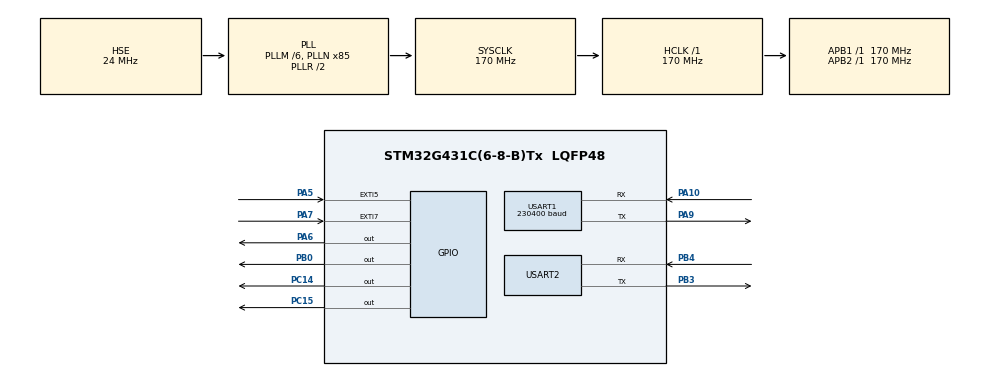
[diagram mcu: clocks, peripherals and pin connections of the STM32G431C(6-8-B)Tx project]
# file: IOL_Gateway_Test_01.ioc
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Dma.Request0=USART1_RX
Dma.Request1=USART2_RX
Dma.USART1_RX.0.Direction=DMA_PERIPH_TO_MEMORY
Dma.USART1_RX.0.EventEnable=DISABLE
Dma.USART1_RX.0.Instance=DMA1_Channel1
Dma.USART1_RX.0.MemDataAlignment=DMA_MDATAALIGN_BYTE
Dma.USART1_RX.0.MemInc=DMA_MINC_ENABLE
Dma.USART1_RX.0.Mode=DMA_NORMAL
Dma.USART1_RX.0.PeriphDataAlignment=DMA_PDATAALIGN_BYTE
Dma.USART1_RX.0.PeriphInc=DMA_PINC_DISABLE
Dma.USART1_RX.0.Polarity=HAL_DMAMUX_REQ_GEN_RISING
Dma.USART1_RX.0.Priority=DMA_PRIORITY_LOW
Dma.USART1_RX.0.RequestNumber=1
Dma.USART1_RX.0.SignalID=NONE
Dma.USART1_RX.0.SyncEnable=DISABLE
Dma.USART1_RX.0.SyncPolarity=HAL_DMAMUX_SYNC_NO_EVENT
Dma.USART1_RX.0.SyncRequestNumber=1
Dma.USART1_RX.0.SyncSignalID=NONE
Dma.USART2_RX.1.Direction=DMA_PERIPH_TO_MEMORY
Dma.USART2_RX.1.EventEnable=DISABLE
Dma.USART2_RX.1.Instance=DMA1_Channel2
Dma.USART2_RX.1.MemDataAlignment=DMA_MDATAALIGN_BYTE
Dma.USART2_RX.1.MemInc=DMA_MINC_ENABLE
Dma.USART2_RX.1.Mode=DMA_NORMAL
Dma.USART2_RX.1.PeriphDataAlignment=DMA_PDATAALIGN_BYTE
Dma.USART2_RX.1.PeriphInc=DMA_PINC_DISABLE
Dma.USART2_RX.1.Polarity=HAL_DMAMUX_REQ_GEN_RISING
Dma.USART2_RX.1.Priority=DMA_PRIORITY_LOW
Dma.USART2_RX.1.RequestNumber=1
Dma.USART2_RX.1.SignalID=NONE
Dma.USART2_RX.1.SyncEnable=DISABLE
Dma.USART2_RX.1.SyncPolarity=HAL_DMAMUX_SYNC_NO_EVENT
Dma.USART2_RX.1.SyncRequestNumber=1
Dma.USART2_RX.1.SyncSignalID=NONE
Mcu.Family=STM32G4
Mcu.Name=STM32G431C(6-8-B)Tx
Mcu.Package=LQFP48
NVIC.DMA1_Channel1_IRQn=true\:0\:0\:false\:false\:true\:false\:true\:true
NVIC.DMA1_Channel2_IRQn=true\:0\:0\:false\:false\:true\:false\:true\:true
NVIC.EXTI9_5_IRQn=true\:0\:0\:false\:false\:true\:true\:true\:true
NVIC.PriorityGroup=NVIC_PRIORITYGROUP_4
NVIC.TIM1_UP_TIM16_IRQn=true\:0\:0\:false\:false\:true\:true\:true\:true
NVIC.USART1_IRQn=true\:0\:0\:false\:false\:true\:true\:true\:true
NVIC.USART2_IRQn=true\:0\:0\:false\:false\:true\:true\:true\:true
PA10.Mode=Asynchronous
PA10.Signal=USART1_RX
PA13.Mode=Serial_Wire
PA13.Signal=SYS_JTMS-SWDIO
PA14.Mode=Serial_Wire
PA14.Signal=SYS_JTCK-SWCLK
PA5.Signal=GPXTI5
PA6.Signal=GPIO_Output
PA7.Signal=GPXTI7
PA9.Mode=Asynchronous
PA9.Signal=USART1_TX
PB0.Signal=GPIO_Output
PB3.Mode=Asynchronous
PB3.Signal=USART2_TX
PB4.Mode=Asynchronous
PB4.Signal=USART2_RX
PC14-OSC32_IN.Signal=GPIO_Output
PC15-OSC32_OUT.Signal=GPIO_Output
PF0-OSC_IN.Mode=HSE-External-Clock-Source
PF0-OSC_IN.Signal=RCC_OSC_IN
ProjectManager.HeapSize=0x200
ProjectManager.StackSize=0x400
ProjectManager.TargetToolchain=STM32CubeIDE
RCC.ADC12Freq_Value=170000000
RCC.AHBFreq_Value=170000000
RCC.APB1Freq_Value=170000000
RCC.APB1TimFreq_Value=170000000
RCC.APB2Freq_Value=170000000
RCC.APB2TimFreq_Value=170000000
RCC.CK48CLockSelection=RCC_USBCLKSOURCE_HSI48
RCC.CortexFreq_Value=170000000
RCC.EXTERNAL_CLOCK_VALUE=12288000
RCC.HCLKFreq_Value=170000000
RCC.HSE_VALUE=24000000
RCC.HSI48_VALUE=48000000
RCC.HSI_VALUE=16000000
RCC.LSE_VALUE=32768
RCC.PLLM=RCC_PLLM_DIV6
RCC.PLLN=85
RCC.PLLQ=RCC_PLLQ_DIV4
RCC.PLLSourceVirtual=RCC_PLLSOURCE_HSE
RCC.SYSCLKFreq_VALUE=170000000
RCC.SYSCLKSource=RCC_SYSCLKSOURCE_PLLCLK
RCC.USBFreq_Value=48000000
RCC.VCOOutputFreq_Value=340000000
TIM1.PeriodNoDither=170-1
TIM1.Prescaler=1000-1
USART1.BaudRate=230400
USART1.Parity=PARITY_EVEN
USART1.VirtualMode-Asynchronous=VM_ASYNC
USART1.WordLength=WORDLENGTH_9B
USART2.VirtualMode-Asynchronous=VM_ASYNC
VP_SYS_VS_DBSignals.Mode=DisableDeadBatterySignals
VP_TIM1_VS_ClockSourceINT.Mode=Internal
board=custom

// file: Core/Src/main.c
/* USER CODE BEGIN Header */
/**
  ******************************************************************************
  * @file           : main.c
  * @brief          : Main program body
  ******************************************************************************
  * @attention
  *
  * Copyright (c) 2024 STMicroelectronics.
  * All rights reserved.
  *
  * This software is licensed under terms that can be found in the LICENSE file
  * in the root directory of this software component.
  * If no LICENSE file comes with this software, it is provided AS-IS.
  *
  ******************************************************************************
  */
/* USER CODE END Header */
#include "main.h"
#include "dma.h"
#include "tim.h"
#include "usart.h"
#include "gpio.h"

void SystemClock_Config(void);

int main(void)
{

  /* MCU Configuration--------------------------------------------------------*/

  /* Reset of all peripherals, Initializes the Flash interface and the Systick. */
  HAL_Init();

  /* Configure the system clock */
  SystemClock_Config();

  /* Initialize all configured peripherals */
  MX_GPIO_Init();
  MX_DMA_Init();
  MX_USART1_UART_Init();
  MX_TIM1_Init();
  MX_USART2_UART_Init();
  /* USER CODE BEGIN 2 */
  IOL_ConnectToIFM_Read();
  IOL_ParameterValue_Init();
  // Q_Init(&USB_TX_Q, (uint8_t *) USB_TX_Data, quedata_arraylength);

  HAL_Delay(3000);
  HAL_TIM_Base_Start_IT(&htim1);
  // GetClockSourcePrint();
  // BootMessagePrint();

  HAL_UARTEx_ReceiveToIdle_DMA(&huart2, (uint8_t *)uart2_rx_IDLE_buf, UART_RX_IDLE_BUFSIZE);
  __HAL_DMA_DISABLE_IT(&hdma_usart2_rx, DMA_IT_HT);
  HAL_UARTEx_ReceiveToIdle_DMA(&huart1, (uint8_t *)uart1_rx_IDLE_buf, UART_RX_IDLE_BUFSIZE);
  __HAL_DMA_DISABLE_IT(&hdma_usart1_rx, DMA_IT_HT);
  // HAL_GPIO_WritePin(GPIOA, GPIO_PIN_6, GPIO_PIN_SET);
  /* USER CODE END 2 */

  /* Infinite loop */
  /* USER CODE BEGIN WHILE */
  while (1)
  {
    User_Toggle_Led();
    ProcessDataIn_IncreaseCntValue();
    General_IOL_Process();
    // HAL_Delay(500);
    // HAL_GPIO_TogglePin(GPIOC, GPIO_PIN_14);
    // HAL_GPIO_TogglePin(GPIOC, GPIO_PIN_15);
    /* USER CODE END WHILE */

  }
}

void SystemClock_Config(void)
{
  RCC_OscInitTypeDef RCC_OscInitStruct = {0};
  RCC_ClkInitTypeDef RCC_ClkInitStruct = {0};

  /** Configure the main internal regulator output voltage
  */
  HAL_PWREx_ControlVoltageScaling(PWR_REGULATOR_VOLTAGE_SCALE1_BOOST);

  /** Initializes the RCC Oscillators according to the specified parameters
  * in the RCC_OscInitTypeDef structure.
  */
  RCC_OscInitStruct.OscillatorType = RCC_OSCILLATORTYPE_HSE;
  RCC_OscInitStruct.HSEState = RCC_HSE_BYPASS;
  RCC_OscInitStruct.PLL.PLLState = RCC_PLL_ON;
  RCC_OscInitStruct.PLL.PLLSource = RCC_PLLSOURCE_HSE;
  RCC_OscInitStruct.PLL.PLLM = RCC_PLLM_DIV6;
  RCC_OscInitStruct.PLL.PLLN = 85;
  RCC_OscInitStruct.PLL.PLLP = RCC_PLLP_DIV2;
  RCC_OscInitStruct.PLL.PLLQ = RCC_PLLQ_DIV4;
  RCC_OscInitStruct.PLL.PLLR = RCC_PLLR_DIV2;
  if (HAL_RCC_OscConfig(&RCC_OscInitStruct) != HAL_OK)
  {
    Error_Handler();
  }

  /** Initializes the CPU, AHB and APB buses clocks
  */
  RCC_ClkInitStruct.ClockType = RCC_CLOCKTYPE_HCLK|RCC_CLOCKTYPE_SYSCLK
                              |RCC_CLOCKTYPE_PCLK1|RCC_CLOCKTYPE_PCLK2;
  RCC_ClkInitStruct.SYSCLKSource = RCC_SYSCLKSOURCE_PLLCLK;
  RCC_ClkInitStruct.AHBCLKDivider = RCC_SYSCLK_DIV1;
  RCC_ClkInitStruct.APB1CLKDivider = RCC_HCLK_DIV1;
  RCC_ClkInitStruct.APB2CLKDivider = RCC_HCLK_DIV1;

  if (HAL_RCC_ClockConfig(&RCC_ClkInitStruct, FLASH_LATENCY_4) != HAL_OK)
  {
    Error_Handler();
  }
}

void Error_Handler(void)
{
  __disable_irq();
  while (1)
  {
  }
}
